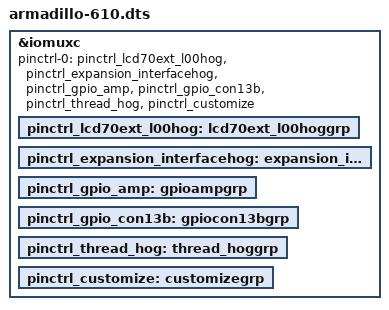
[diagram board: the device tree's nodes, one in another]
// SPDX-License-Identifier: (GPL-2.0 OR MIT)
/*
 * Copyright (C) 2023 Atmark Techno, Inc. All Rights Reserved.
 */

/dts-v1/;

#include "armadillo-610.dtsi"
#include "armadillo-640-default-console.dtsi"

&iomuxc {
	pinctrl-names = "default";
	pinctrl-0 = <
		&pinctrl_lcd70ext_l00hog
		&pinctrl_expansion_interfacehog
		&pinctrl_gpio_amp
		&pinctrl_gpio_con13b
		&pinctrl_thread_hog
		&pinctrl_customize
	>;

	pinctrl_lcd70ext_l00hog: lcd70ext_l00hoggrp {
		/* this group left empty for lcd70ext-l00 GPIOs */
	};

	pinctrl_expansion_interfacehog: expansion_interfacehoggrp {
		/* this group left empty for at-dtweb expansion GPIOs */
	};

	pinctrl_gpio_amp: gpioampgrp {
		/* this group left empty for armadillo-610-extboard-eva amp GPIOs */
	};

	pinctrl_gpio_con13b: gpiocon13bgrp {
		/* this group left empty for armadillo-610-extboard-eva con13b GPIOs */
	};

	pinctrl_thread_hog: thread_hoggrp {
		/* this group left empty for armadillo-*-thread* */
	};

	pinctrl_customize: customizegrp {
		/* this group left empty for armadillo-600-customize */
	};
};
